# A64 register map
Vendor: Allwinner; Series: A64; File version: 0.1
CPU: CA53 0, little endian, MPU, no FPU, 0 interrupt priority bits
Registers are 32-bit, read-write, reset 0x0 unless marked. A register's access mark holds for its fields unless they carry their own. Offsets are from the block's base; [hi:lo] are bit positions.

## SMHC0
Base 0x01C0F000
Same registers: SMHC1 0x01C10000, SMHC2 0x01C11000
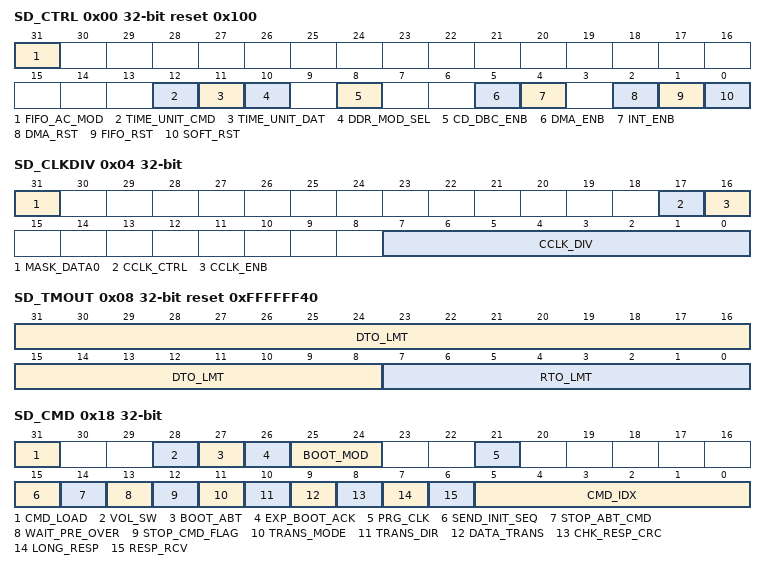
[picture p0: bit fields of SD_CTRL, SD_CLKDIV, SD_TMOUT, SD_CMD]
0x00 SD_CTRL reset 0x100
  [31] FIFO_AC_MOD — FIFO Access Mode 1: AHB bus 0: DMA bus
    1=AHB (AHB bus); 0=DMA (DMA bus)
  [12] TIME_UNIT_CMD — Time unit for command line Time unit used to calculate command line time out value defined in RTO_LMT. 0: 1 card clock period 1: 256 card clock period
    0=1 card clock period; 1=256 card clock period
  [11] TIME_UNIT_DAT — Time unit for data line Time unit used to calculate data line time out value defined in DTO_LMT. 0: 1 card clock period 1: 256 card clock period
    0=1 card clock period; 1=256 card clock period
  [10] DDR_MOD_SEL — DDR Mode Select Although eMMC`s HS400 speed mode is 8-bit DDR, this filed should be cleared when is set. 0: SDR mode 1: DDR mode
    0=SDR_mode; 1=DDR_mode
  [8] CD_DBC_ENB — Card Detect (Data[3] status) De-bounce Enable 0: disable de-bounce 1: enable de-bounce
    0=disable de-bounce; 1=enable de-bounce
  [5] DMA_ENB — DMA Global Enable 0: Disable DMA to transfer data, using AHB bus 1: Enable DMA to transfer data
    0=Disable DMA to transfer data, using AHB bus; 1=Enable DMA to transfer data
  [4] INT_ENB — Global Interrupt Enable 0: Disable interrupts 1: Enable interrupts
    0=Disable interrupts; 1=Enable interrupts
  [2] DMA_RST — DMA Reset
  [1] FIFO_RST — FIFO Reset 0: No change 1: Reset FIFO
    0=No_change; 1=Reset FIFO
  [0] SOFT_RST — Software Reset 0: No change 1: Reset SD/MMC controller
    0=No_change; 1=Reset SD/MMC controller
0x04 SD_CLKDIV
  [31] MASK_DATA0 — 0 : Do not mask data0 when updata clock ; 1 : Mask data0 when updata clock; Default : 0;
  [17] CCLK_CTRL — Card Clock Output Control 0 : Card clock always on 1 : Turn off card clock when FSM in IDLE state
  [16] CCLK_ENB — Card Clock Enable 0 : Card Clock off 1 : Card Clock on
  [7:0] CCLK_DIV — Card clock divider n : Source clock is divided by 2*n.(n=0~255) when is set, this field must be cleared.
0x08 SD_TMOUT reset 0xFFFFFF40
  [31:8] DTO_LMT — Data Timeout Limit
  [7:0] RTO_LMT — Response Timeout Limit
0x0C SD_CTYPE
  [1:0] CARD_WID — Card width 2`b00 : 1-bit width 2`b01 : 4-bit width 2`b1x : 8-bit width
0x10 SD_BLKSIZ reset 0x200
  [15:0] BLK_SZ — Block size
0x14 SD_BYTCNT reset 0x200
  [31:0] BYTE_CNT — Byte counter Number of bytes to be transferred; should be integer multiple of Block Size(BLK_SZ) for block transfers.
0x18 SD_CMD
  [31] CMD_LOAD — Start Command. This bit is auto cleared when current command is sent. If there is no any response error happened, a command complete interrupt bit (CMD_OVER) will be set in register. You should not write any other command before this bit is cleared, or when a command busy interrupt bit (CMD_BUSY) will be set in register.
  [28] VOL_SW — Voltage Switch 0: normal command 1: Voltage switch command, set for CMD11 only
    0=normal command; 1=Voltage switch command, set for CMD11 only
  [27] BOOT_ABT — Boot Abort Setting this bit will terminate the boot operation.
  [26] EXP_BOOT_ACK — Expect Boot Acknowledge. When Software sets this bit along in mandatory boot operation, controller expects a boot acknowledge start pattern of 0-1-0 from the selected card.
  [25:24] BOOT_MOD — Boot Mode 2`b00: Normal command 2`b01: Mandatory Boot operation 2`b10: Alternate Boot operation 2`b11: Reserved
  [21] PRG_CLK — Change Clock 0: Normal command 1: Change Card Clock; when this bit is set, controller will change clock domain and clock output. No command will be sent.
    0=Normal command; 1=Change Card Clock; when this bit is set, controller will change clock domain and clock output. No command will be sent.
  [15] SEND_INIT_SEQ — Send Initialization 0: normal command sending 1: Send initialization sequence before sending this command.
    0=normal command sending; 1=Send initialization sequence before sending this command
  [14] STOP_ABT_CMD — Stop Abort Command 0: normal command sending 1:send Stop or abort command to stop current data transfer in progress.(CMD12, CMD52 for writing `I/O Abort` in SDIO CCCR)
    0=normal command sending 1:send Stop or abort command to stop current data transfer in progress.(CMD12, CMD52 for writing `I/O Abort` in SDIO CCCR)
  [13] WAIT_PRE_OVER — Wait Data Transfer Over 0: Send command at once, do not care of data transferring 1: Wait for data transfer completion before sending current command
    0=Send command at once, do not care of data transferring; 1=Wait for data transfer completion before sending current command
  [12] STOP_CMD_FLAG — Send Stop CMD Automatically (CMD12) 0: Do not send stop command at end of data transfer 1: Send stop command automatically at end of data transfer
    0=Do not send stop command at end of data transfer; 1=Send stop command automatically at end of data transfer
  [11] TRANS_MODE — Transfer Mode 0: Block data transfer command 1: Stream data transfer command
    0=Block data transfer command; 1=Stream data transfer command
  [10] TRANS_DIR — Transfer Direction 0: Read operation 1: Write operation
    0=Read operation; 1=Write operation
  [9] DATA_TRANS — Data Transfer 0: without data transfer 1: with data transfer
    0=without data transfer; 1=with data transfer
  [8] CHK_RESP_CRC — Check Response CRC 0: Do not check response CRC 1: Check response CRC
    0=Do not check response CRC; 1=Check response CRC
  [7] LONG_RESP — Response Type 0:Short Response (48 bits) 1:Long Response (136 bits)
  [6] RESP_RCV — Response Receive 0: Command without Response 1: Command with Response
    0=Command_without_Response; 1=Command_with_Response
  [5:0] CMD_IDX — CMD Index Command index value
0x1C SD_CMDARG
  [31:0] CMD_ARG — Command argument
0x20 SD_RESP0
  [31:0] CMD_RESP0 ro — response 0 Bit[31:0] of response
0x24 SD_RESP1
  [31:0] CMD_RESP1 ro — response 1 Bit[63:31] of response
0x28 SD_RESP2
  [31:0] CMD_RESP2 ro — response 2 Bit[95:64] of response
0x2C SD_RESP3
  [31:0] CMD_RESP3 ro — response 3 Bit[127:96] of response
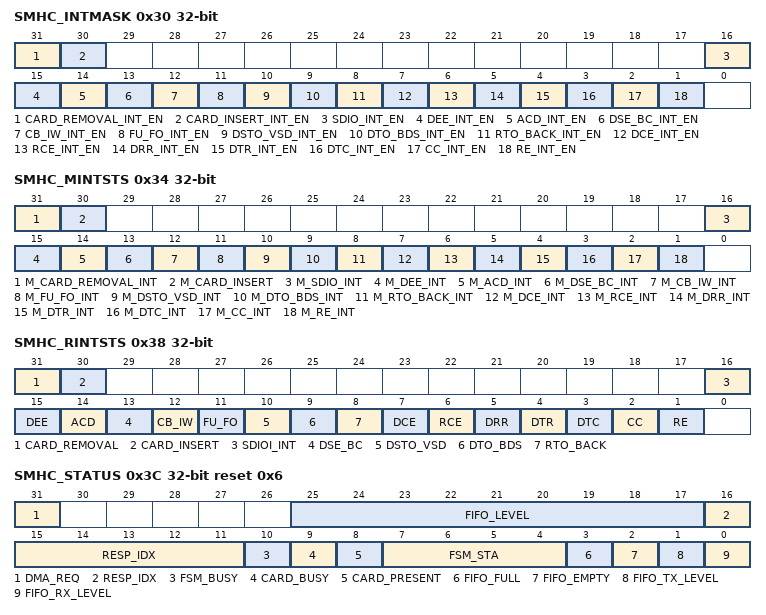
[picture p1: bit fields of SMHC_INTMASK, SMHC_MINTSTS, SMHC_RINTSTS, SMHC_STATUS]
0x30 SMHC_INTMASK — Interrupt mask register
  [31] CARD_REMOVAL_INT_EN — Card Removed Interrupt Enable
  [30] CARD_INSERT_INT_EN — Card Inserted Interrupt Enable
  [16] SDIO_INT_EN — SDIO Interrupt Enable
  [15] DEE_INT_EN — Data End-bit Error Interrupt Enable
  [14] ACD_INT_EN — Auto Command Done Interrupt Enable
  [13] DSE_BC_INT_EN — Data Start Error Interrupt Enable
  [12] CB_IW_INT_EN — Command Busy and Illegal Write Interrupt Enable
  [11] FU_FO_INT_EN — FIFO Underrun/Overflow Interrupt Enable
  [10] DSTO_VSD_INT_EN — Data Starvation Timeout/V1.8 Switch Done Interrupt Enable
  [9] DTO_BDS_INT_EN — Data Timeout/Boot Data Start Interrupt Enable
  [8] RTO_BACK_INT_EN — Response Timeout/Boot ACK Received Interrupt Enable
  [7] DCE_INT_EN — Data CRC Error Interrupt Enable
  [6] RCE_INT_EN — Response CRC Error Interrupt Enable
  [5] DRR_INT_EN — Data Receive Request Interrupt Enable
  [4] DTR_INT_EN — Data Transmit Request Interrupt Enable
  [3] DTC_INT_EN — Data Transfer Complete Interrupt Enable
  [2] CC_INT_EN — Command Complete Interrupt Enable
  [1] RE_INT_EN — Response Error Interrupt Enable
0x34 SMHC_MINTSTS — Masked interrupt status register
  [31] M_CARD_REMOVAL_INT — Card Removed
  [30] M_CARD_INSERT — Card Inserted
  [16] M_SDIO_INT — SDIO Interrupt
  [15] M_DEE_INT — Data End-bit Error When set during receiving data, it means that host controller does not receive valid data end bit. When set during transmitting data, it means that host controller does not receive CRC status taken or received CRC status taken is negative.
  [14] M_ACD_INT — Auto Command Done When set, it means auto stop command(CMD12) completed.
  [13] M_DSE_BC_INT — Data Start Error When set during receiving data, it means that host controller found a error start bit. When set during transmitting data, it means that busy signal is cleared.
  [12] M_CB_IW_INT — Command Busy and Illegal Write
  [11] M_FU_FO_INT — FIFO Underrun/Overflow
  [10] M_DSTO_VSD_INT — Data Starvation Timeout/V1.8 Switch Done
  [9] M_DTO_BDS_INT — Data Timeout/Boot Data Start
  [8] M_RTO_BACK_INT — Response Timeout/Boot ACK Received
  [7] M_DCE_INT — Data CRC Error When set during receiving data, it means that the received data have data CRC error. When set during transmitting data, it means that the received CRC status taken is negative.
  [6] M_RCE_INT — Response CRC Error
  [5] M_DRR_INT — Data Receive Request When set, it means that there are enough data in FIFO during receiving data.
  [4] M_DTR_INT — Data Transmit Request When set, it means that there are enough space in FIFO during transmitting data.
  [3] M_DTC_INT — Data Transfer Complete
  [2] M_CC_INT — Command Complete
  [1] M_RE_INT — Response Error (no response or response CRC error) When set, Transmit Bit error or End Bit error or CMD Index error may occurs.
0x38 SMHC_RINTSTS — Raw interrupt status register
  [31] CARD_REMOVAL — Card Removed
  [30] CARD_INSERT — Card Inserted
  [16] SDIOI_INT — SDIO Interrupt
  [15] DEE — Data End-bit Error When set during receiving data, it means that host controller does not receive valid data end bit. When set during transmitting data, it means that host controller does not receive CRC status taken.
  [14] ACD — Auto Command Done When set, it means auto stop command(CMD12) completed.
  [13] DSE_BC — Data Start Error When set during receiving data, it means that host controller found a error start bit. When set during transmitting data, it means that busy signal is cleared.
  [12] CB_IW — Command Busy and Illegal Write
  [11] FU_FO — FIFO Underrun/Overflow
  [10] DSTO_VSD — Data Starvation Timeout/V1.8 Switch Done
  [9] DTO_BDS — Data Timeout/Boot Data Start
  [8] RTO_BACK — Response Timeout/Boot ACK Received
  [7] DCE — Data CRC Error When set during receiving data, it means that the received data have data CRC error. When set during transmitting data, it means that the received CRC status taken is negative.
  [6] RCE — Response CRC Error
  [5] DRR — Data Receive Request When set, it means that there are enough data in FIFO during receiving data.
  [4] DTR — Data Transmit Request When set, it means that there are enough space in FIFO during transmitting data.
  [3] DTC — Data Transfer Complete
  [2] CC — Command Complete
  [1] RE — Response Error (no response or response CRC error) When set, Transmit Bit error or End Bit error or CMD Index error may occurs.
0x3C SMHC_STATUS reset 0x6 — Status register
  [31] DMA_REQ ro — DMA Request DMA request signal state
  [25:17] FIFO_LEVEL ro — FIFO Level Number of filled locations in FIFO
  [16:11] RESP_IDX ro — Response Index Index of previous response, including any auto-stop sent by controller
  [10] FSM_BUSY ro — Data FSM Busy Data transmit or receive state-machine is busy
  [9] CARD_BUSY ro — Card data busy Inverted version of DATA[0] 0: card data not busy 1: card data busy
    0=card_data_not_busy; 1=card_data_busy
  [8] CARD_PRESENT ro — Data[3] status level of DATA[3]; checks whether card is present 0: card not present 1: card present
    0=card_not_present; 1=card_present
  [7:4] FSM_STA ro — Command FSM states: 0: Idle 1: Send init sequence 2: TX CMD start bit 3: TX CMD TX bit 4: TX CMD index + argument 5: TX CMD CRC7 6: TX CMD end bit 7: RX response start bit 8: RX response IRQ response 9: RX response TX bit 10: RX response CMD index 11: RX response data 12: RX response CRC7 13: RX response end bit 14: CMD path wait NCC 15: Wait; CMD-to-response turnaround
  [3] FIFO_FULL ro — FIFO full 1: FIFO full 0: FIFO not full
    1=FIFO_full; 0=FIFO (FIFO not full)
  [2] FIFO_EMPTY ro — FIFO Empty 1 - FIFO Empty 0 - FIFO not Empty
  [1] FIFO_TX_LEVEL ro — FIFO TX Water Level flag 0: FIFO didn`t reach transmit trigger level 1: FIFO reached transmit trigger level
    0=FIFO didn`t reach transmit trigger level; 1=FIFO reached transmit trigger level
  [0] FIFO_RX_LEVEL ro — FIFO RX Water Level flag 0: FIFO didn`t reach receive trigger level 1: FIFO reached receive trigger level
    0=FIFO didn`t reach receive trigger level; 1=FIFO reached receive trigger level
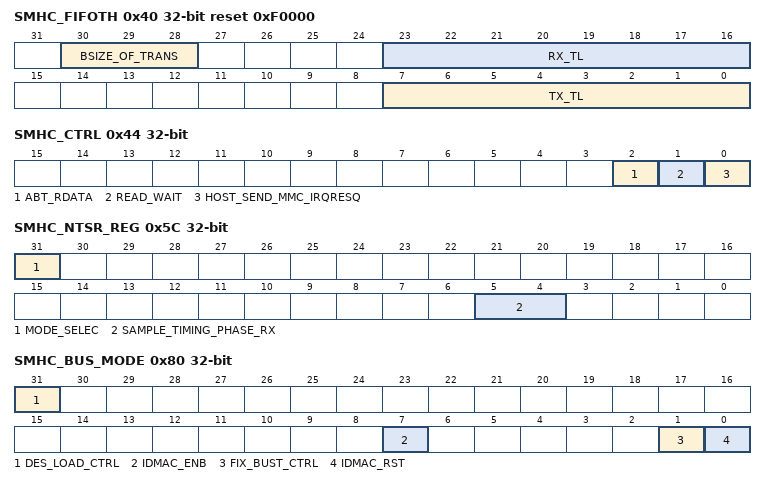
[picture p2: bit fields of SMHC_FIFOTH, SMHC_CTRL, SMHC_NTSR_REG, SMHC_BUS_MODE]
0x40 SMHC_FIFOTH reset 0xF0000 — FIFO water level register
  [30:28] BSIZE_OF_TRANS — Burst size of multiple transaction 3`b000: 1 transfers 3`b001: 4 3`b010: 8 3`b011: 16 Others: Reserved Should be programmed same as DMA controller multiple transaction size. The units for transfers are the DWORD. A single transfer would be signaled based on this value. Value should be sub-multiple of (RX_TL + 1) and (FIFO_DEPTH - TX_TL) Recommended: MSize = 16, TX_TL = 240, RX_TL = 15(for SMHC1 and SMHC2) MSize = 8, TX_TL = 248, RX_TL = 7(for SMHC0)
  [23:16] RX_TL — RX Trigger Level 0x0~0xFE: RX Trigger Level is 0~254 0xFF reserved FIFO threshold when FIFO request host to receive data from FIFO. When FIFO data level is greater than this value, DMA is request is raised if DMA enabled, or RX interrupt bit is set if interrupt enabled. At the end of packet, if the last transfer is less than this level, the value is ignored and relative request will be raised as usual. Recommended: 15 (means greater than 15, for SMHC1 and SMHC2) 7 (means greater than 7, for SMHC0)
  [7:0] TX_TL — TX Trigger Level 0x1~0xFF: TX Trigger Level is 1~255 0x0: no trigger FIFO threshold when FIFO requests host to transmit data to FIFO. When FIFO data level is less than or equal to this value, DMA TX request is raised if DMA enabled, or TX request interrupt bit is set if interrupt enabled. At the end of packet, if the last transfer is less than this level, the value is ignored and relative request will be raised as usual. Recommended: 240(means less than or equal to 240, for SMHC1 and SMHC2) 248(means less than or equal to 248,for SMHC0)
    0=no trigger FIFO threshold when FIFO requests host to transmit data to FIFO. When FIFO data level is less than or equal to this value, DMA TX request is raised if DMA enabled, or TX request interrupt bit is set if interrupt enabled. At the end of packet, if the last transfer is less than this level, the value is ignored and relative request will be raised as usual. Recommended: 240(means less than or equal to 240, for SMHC1 and SMHC2) 248(means less than or equal to 248,for SMHC0)
0x44 SMHC_CTRL — Control register
  [2] ABT_RDATA — Abort Read Data 0: Ignored 1: After suspend command is issued during read-transfer, software polls card to find when suspend happened. Once suspend occurs, software sets bit to reset data state-machine, which is waiting for next block of data. Used in SDIO card suspends sequence.
    0=Ignored; 1=After suspend command is issued during read-transfer, software polls card to find when suspend happened. Once suspend occurs, software sets bit to reset data state-machine, which is waiting for next block of data. Used in SDIO card suspends sequence.
  [1] READ_WAIT — Read Wait 0: Clear SDIO read wait 1: Assert SDIO read wait
    0=Clear SDIO read wait; 1=Assert SDIO read wait
  [0] HOST_SEND_MMC_IRQRESQ — Host Send MMC IRQ Response 0: Ignored 1: Send auto IRQ response When host is waiting MMC card interrupt response, setting this bit will make controller cancel wait state and return to idle state, at which time, controller will receive IRQ response sent by itself.
    0=Ignored; 1=Send auto IRQ response When host is waiting MMC card interrupt response, setting this bit will make controller cancel wait state and return to idle state, at which time, controller will receive IRQ response sent by itself
0x48 SMHC_TBC0 — Transferred byte count0 between controller and card
  [31:0] TBC0 ro — Transferred Count 0 Number of bytes transferred between card and internal FIFO. The register should be accessed in full to avoid read-coherency problems and read only after data transfer completes.
0x4C SMHC_TBC1 — Transferred byte count1 between host memory and internal FIFO
  [31:0] TBC1 ro — Transferred Count 1 Number of bytes transferred between Host/DMA memory and internal FIFO. The register should be accessed in full to avoid read-coherency problems and read only after data transfer completes.
0x54 SMHC_CSDC reset 0x3 — CRC status detect control register(only for SMHC2)
  [3:0] CRC_DET_PARA — 0x6:HS400 speed mode 0x3:Other speed mode
0x58 SMHC_A12A reset 0xFFFF — Auto command 12 argument register
  [15:0] SD_A12A — SD_A12A set the argument of command 12 automatically send by controller
0x5C SMHC_NTSR_REG
  [31] MODE_SELEC — 0: Old mode of Sample/Output Timing ; 1: New mode of Sample/Output Timing; Default value : 0;
    0=Old mode of Sample/Output Timing ;; 1=New mode of Sample/Output Timing; Default value : 0;
  [5:4] SAMPLE_TIMING_PHASE_RX — SAMPLE_TIMING_PHASE(RX) 00: Sample timing phase offset 90 ; 01: Sample timing phase offset 180 ; 10: Sample timing phase offset 270 ; 11: Ignore; Default value: 00;
0x78 SMHC_HWRST reset 0x1 — Hardware reset register
  [0] HW_RESET — 1 : Active mode 0 : Reset These bits cause the cards to enter pre-idle state, which requires them to be re-initialized.
0x80 SMHC_BUS_MODE
  [31] DES_LOAD_CTRL wo — When DMAC fetches a descriptor, if the valid bit of a descriptor is not set, DMAC FSM will go to the suspend state. Setting this bit will make DMAC re-fetch descriptor again and do the transfer normally.
  [7] IDMAC_ENB — IDMAC Enable. When set, the IDMAC is enabled. DE is read/write.
  [1] FIX_BUST_CTRL — Fixed Burst. Controls whether the AHB Master interface performs fixed burst transfers or not. When set, the AHB will use only SINGLE, INCR4, INCR8 during start of normal burst transfers. When reset, the AHB will use SINGLE and INCR burst transfer operations.
  [0] IDMAC_RST — DMA Reset. When set, the DMA Controller resets all its internal registers. SWR is read/write. It is automatically cleared after 1 clock cycle.
0x84 SMHC_DLBA_REG
  [31:0] DES_BASE_ADDR — Start of Descriptor List. Contains the base address of the First Descriptor. The LSB bits [1:0] are ignored and taken as all-zero by the IDMAC internally. Hence these LSB bits are read-only.
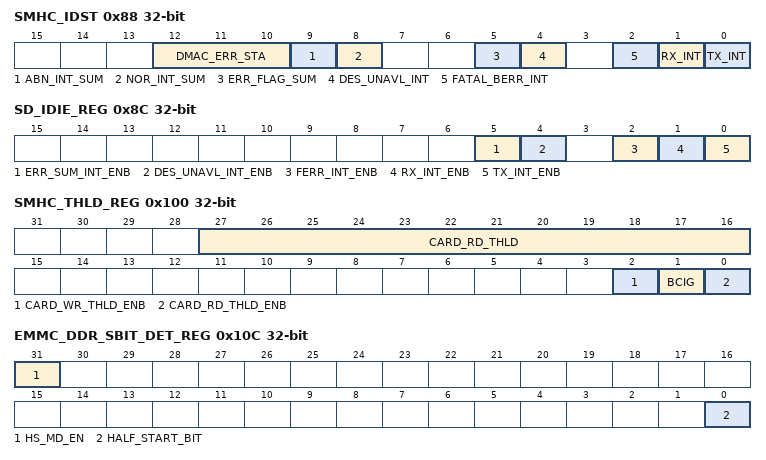
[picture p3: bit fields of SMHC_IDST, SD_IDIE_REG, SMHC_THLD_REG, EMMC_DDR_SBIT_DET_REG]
0x88 SMHC_IDST — DMAC status register
  [12:10] DMAC_ERR_STA ro — Error Bits. Indicates the type of error that caused a Bus Error. Valid only with ( [2]) set. This field does not generate an interrupt. 3`b001: Host Abort received during transmission 3`b010: Host Abort received during reception Others: Reserved EB is read-only.
  [9] ABN_INT_SUM — Abnormal Interrupt Summary. Logical OR of the following: [2]: Fatal Bus Interrupt [4]: DU bit Interrupt [5]: Card Error Summary Interrupt Only unmasked bits affect this bit. This is a sticky bit and must be cleared each time a corresponding bit that causes AIS to be set is cleared. Writing a 1 clears this bit.
  [8] NOR_INT_SUM — Normal Interrupt Summary. Logical OR of the following: [0]: Transmit Interrupt [1]: Receive Interrupt Only unmasked bits affect this bit. This is a sticky bit and must be cleared each time a corresponding bit that causes NIS to be set is cleared. Writing a 1 clears this bit.
  [5] ERR_FLAG_SUM — Card Error Summary. Indicates the status of the transaction to/from the card; also present in RINTSTS. Indicates the logical OR of the following bits: EBE: End Bit Error RTO: Response Timeout/Boot ACK Timeout RCRC: Response CRC SBE: Start Bit Error DRTO: Data Read Timeout/BDS timeout DCRC: Data CRC for Receive RE: Response Error Writing a 1 clears this bit.
  [4] DES_UNAVL_INT — Descriptor Unavailable Interrupt. This bit is set when the descriptor is unavailable due to OWN bit = 0 (DES0[31] =0). Writing a 1 clears this bit.
  [2] FATAL_BERR_INT — Fatal Bus Error Interrupt. Indicates that a Bus Error occurred ( [12:10]). When this bit is set, the DMA disables all its bus accesses. Writing a 1 clears this bit.
  [1] RX_INT — Receive Interrupt. Indicates the completion of data reception for a descriptor. Writing a 1 clears this bit.
  [0] TX_INT — Transmit Interrupt. Indicates that data transmission is finished for a descriptor. Writing a `1` clears this bit.
0x8C SD_IDIE_REG
  [5] ERR_SUM_INT_ENB — Card Error summary Interrupt Enable. When set, it enables the Card Interrupt summary.
  [4] DES_UNAVL_INT_ENB — Descriptor Unavailable Interrupt. When set along with Abnormal Interrupt Summary Enable, the DU interrupt is enabled.
  [2] FERR_INT_ENB — Fatal Bus Error Enable. When set with Abnormal Interrupt Summary Enable, the Fatal Bus Error Interrupt is enabled. When reset, Fatal Bus Error Enable Interrupt is disabled.
  [1] RX_INT_ENB — Receive Interrupt Enable. When set with Normal Interrupt Summary Enable, Receive Interrupt is enabled. When reset, Receive Interrupt is disabled.
  [0] TX_INT_ENB — Transmit Interrupt Enable. When set with Normal Interrupt Summary Enable, Transmit Interrupt is enabled. When reset, Transmit Interrupt is disabled.
0x100 SMHC_THLD_REG
  [27:16] CARD_RD_THLD — Card Read Threshold Size
  [2] CARD_WR_THLD_ENB — CARD_WR_THLD_ENB(for SMHC2 only) Card Write Threshold Enable(HS400) 0: Card write threshold disable 1: Card write threshold enabled Host controller initiates write transfer only if card threshold amount of data is available in transmit FIFO.
    0=Card_write_threshold_disable; 1=Card write threshold enabled Host controller initiates write transfer only if card threshold amount of data is available in transmit FIFO
  [1] BCIG — Busy Clear Interrupt Generation 0: Busy Clear Interrupt disabled 1: Busy Clear Interrupt Enabled The application can disable this feature if it does not want to wait for a Busy Clear Interrupt.
    0=Busy_Clear_Interrupt_disabled; 1=Busy Clear Interrupt Enabled The application can disable this feature if it does not want to wait for a Busy Clear Interrupt
  [0] CARD_RD_THLD_ENB — Card Read Threshold Enable 0 : Card Read Threshold Disable 1 : Card Read Threshold Enable Host controller initiates Read Transfer only if amount of space is available in receive FIFO.
0x10C EMMC_DDR_SBIT_DET_REG
  [31] HS_MD_EN — HS400 Mode Enable 0:Disable 1:Enable It is required to set this bit to '1' before initiating any data transfer CMD in HS400 mode.
  [0] HALF_START_BIT — Control for start bit detection mechanism inside mstorage based on duration of start bit. For eMMC 4.5, start bit can be: 0 : Full cycle 1 : Less than one full cycle Set HALF_START_BIT=1 for eMMC 4.5 and above; set to 0 for SD applications.
0x110 RESP_CRC_REG
  [6:0] RESP_CRC ro — Response CRC Response CRC from device.
0x114 DATA7_CRC_REG
  [31:0] DAT7_CRC ro — Data[7] CRC CRC in data[7] form device. In 8bit DDR mode, the higher 16 bits indicate the CRC of even data, and the lower 16 bits indicate the CRC of odd data. In 4 bit DDR mode,it is not used. In SDR mode, the higher 16 bits indicate the CRC of all data.
0x118 DATA6_CRC_REG
  [31:0] DAT6_CRC ro — Data[6] CRC CRC in data[6] form device. In 8bit DDR mode, the higher 16 bits indicate the CRC of even data, and the lower 16 bits indicate the CRC of odd data. In 4 bit DDR mode,it is not used. In SDR mode, the higher 16 bits indicate the CRC of all data.
0x11C DATA5_CRC_REG
  [31:0] DAT5_CRC ro — Data[5] CRC CRC in data[5] form device. In 8bit DDR mode, the higher 16 bits indicate the CRC of even data, and the lower 16 bits indicate the CRC of odd data. In 4 bit DDR mode,it is not used. In SDR mode, the higher 16 bits indicate the CRC of all data.
0x120 DATA4_CRC_REG
  [31:0] DAT4_CRC ro — Data[4] CRC CRC in data[4] form device. In 8 bit DDR mode, the higher 16 bits indicate the CRC of even data, and the lower 16 bits indicate the CRC of odd data. In 4 bit DDR mode, the higher 16 bits indicate the CRC of odd data, and the lower 16 bits indicate the CRC of even data. In SDR mode, the higher 16 bits indicate the CRC of all data.
0x124 DATA3_CRC_REG
  [31:0] DATA3_CRC ro — Data[3] CRC CRC in data[3] from card/eMMC. In 8bit DDR mode,the higher 16 bits indicate the CRC of even data,and the lower 16bits indicate the CRC of odd data. In 4 bit DDR mode,the higher of 16 bits indicate the CRC of odd data, ,and the lower 16bits indicate the CRC of even data. In SDR mode,the higher of 16 bits indicate the CRC of all data.
0x128 DATA2_CRC_REG
  [31:0] DATA2_CRC ro — Data[2] CRC CRC in data[2] from card/eMMC. In 8bit DDR mode,the higher 16 bits indicate the CRC of even data,and the lower 16bits indicate the CRC of odd data. In 4 bit DDR mode,the higher of 16 bits indicate the CRC of odd data, ,and the lower 16bits indicate the CRC of even data. In SDR mode,the higher of 16 bits indicate the CRC of all data.
0x12C DATA1_CRC_REG
  [31:0] DATA1_CRC ro — Data[1] CRC CRC in data[1] from card/eMMC. In 8bit DDR mode,the higher 16 bits indicate the CRC of even data,and the lower 16bits indicate the CRC of odd data. In 4 bit DDR mode,the higher of 16 bits indicate the CRC of odd data, ,and the lower 16bits indicate the CRC of even data. In SDR mode,the higher of 16 bits indicate the CRC of all data.
0x130 DATA0_CRC_REG
  [31:0] DATA0_CRC ro — Data[0] CRC CRC in data[0] from card/eMMC. In 8bit DDR mode,the higher 16 bits indicate the CRC of even data,and the lower 16bits indicate the CRC of odd data. In 4 bit DDR mode,the higher of 16 bits indicate the CRC of odd data, ,and the lower 16bits indicate the CRC of even data. In SDR mode,the higher of 16 bits indicate the CRC of all data.
0x134 CRC_STA_REG
  [2:0] CRC_STA ro — CRC Status CRC status from card/eMMC in write operation Positive CRC status token:3`b010 Negative CRC status token:3`b101
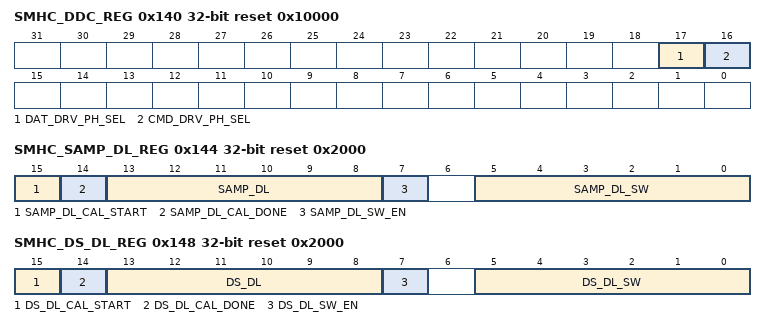
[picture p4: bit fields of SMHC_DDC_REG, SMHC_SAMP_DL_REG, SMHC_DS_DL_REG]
0x140 SMHC_DDC_REG reset 0x10000
  [17] DAT_DRV_PH_SEL — Data Drive Phase Select 0: Drive phase offset is 90 1: Drive phase select is 180 In DDR mode, only 90 phase offset is valid.
    0=Drive phase offset is 90; 1=Drive phase select is 180 In DDR mode, only 90 phase offset is valid
  [16] CMD_DRV_PH_SEL — Command Drive Phase Select 0: Drive phase offset is 90 1: Drive phase select is 180
    0=Drive phase offset is 90; 1=Drive phase select is 180
0x144 SMHC_SAMP_DL_REG reset 0x2000
  [15] SAMP_DL_CAL_START — Sample Delay Calibration Start When set, start sample delay chain calibration.
  [14] SAMP_DL_CAL_DONE ro — Sample Delay Calibration Done When set, it means that sample delay chain calibration is done and the result of calibration is shown in .
  [13:8] SAMP_DL ro — Sample Delay It indicates the number of delay cells corresponding to current card clock. The delay time generated by these delay cells is equal to the cycle of card clock nearly. Generally, it is necessary to do drive delay calibration when card clock is changed. This bit is valid only when is set.
  [7] SAMP_DL_SW_EN — Sample Delay Software Enable When set, enable smaple delay specified at .
  [5:0] SAMP_DL_SW — Sample Delay Software The relative delay between clock line and command line, data lines. It can be determined according to the value of , the cycle of card clock and device`s input timing requirement.
0x148 SMHC_DS_DL_REG reset 0x2000
  [15] DS_DL_CAL_START — Data Strobe Delay Calibration Start When set, start sample delay chain calibration.
  [14] DS_DL_CAL_DONE ro — Data Strobe Delay Calibration Done When set, it means that sample delay chain calibration is done.
  [13:8] DS_DL ro — Data Strobe Delay
  [7] DS_DL_SW_EN — Data Strobe Delay Software Enable
  [5:0] DS_DL_SW — Data Strobe Delay Software
0x200 SMHC_FIFO_REG
  [31:0] TX/RX_FIFO — Data FIFO
